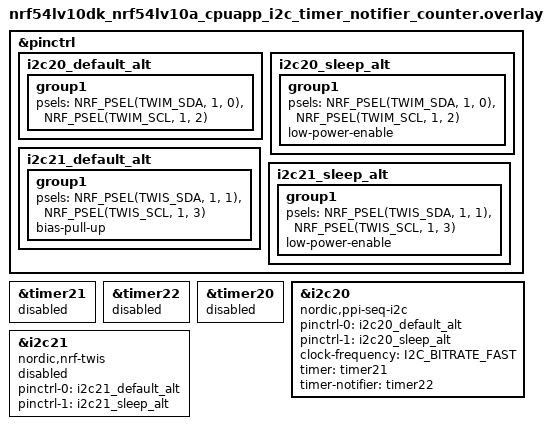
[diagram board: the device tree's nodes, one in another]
/*
 * Copyright (c) 2026 Nordic Semiconductor ASA
 *
 * SPDX-License-Identifier: LicenseRef-Nordic-5-Clause
 */

/* Test requires loopbacks:
 * - between P1.00 and P1.01
 * - between P1.02 and P1.03
 */

&pinctrl {
	i2c20_default_alt: i2c20_default_alt {
		group1 {
			psels = <NRF_PSEL(TWIM_SDA, 1, 0)>,
				<NRF_PSEL(TWIM_SCL, 1, 2)>;
		};
	};

	i2c20_sleep_alt: i2c20_sleep_alt {
		group1 {
			psels = <NRF_PSEL(TWIM_SDA, 1, 0)>,
				<NRF_PSEL(TWIM_SCL, 1, 2)>;
			low-power-enable;
		};
	};

	i2c21_default_alt: i2c21_default_alt {
		group1 {
			psels = <NRF_PSEL(TWIS_SDA, 1, 1)>,
				<NRF_PSEL(TWIS_SCL, 1, 3)>;
			bias-pull-up;
		};
	};

	i2c21_sleep_alt: i2c21_sleep_alt {
		group1 {
			psels = <NRF_PSEL(TWIS_SDA, 1, 1)>,
				<NRF_PSEL(TWIS_SCL, 1, 3)>;
			low-power-enable;
		};
	};
};

/* Timer used for triggering tasks in the PPI sequencer. */
&timer21 {
	status = "reserved";
};

/* Timer used for counting end events in the PPI sequencer. */
&timer22 {
	status = "reserved";
};

test_timer: &timer20 {
	status = "reserved";
};

dut: &i2c20 {
	compatible = "nordic,ppi-seq-i2c";
	status = "okay";
	pinctrl-0 = <&i2c20_default_alt>;
	pinctrl-1 = <&i2c20_sleep_alt>;
	pinctrl-names = "default", "sleep";
	clock-frequency = <I2C_BITRATE_FAST>;
	timer = <&timer21>;
	timer-notifier = <&timer22>;
};

tester: &i2c21 {
	compatible = "nordic,nrf-twis";
	status = "reserved";
	pinctrl-0 = <&i2c21_default_alt>;
	pinctrl-1 = <&i2c21_sleep_alt>;
	pinctrl-names = "default", "sleep";
};
